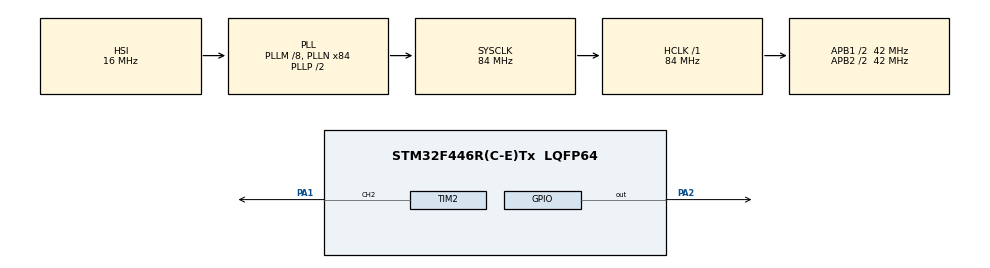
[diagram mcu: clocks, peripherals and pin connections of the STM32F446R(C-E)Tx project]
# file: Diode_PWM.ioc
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Mcu.Family=STM32F4
Mcu.Name=STM32F446R(C-E)Tx
Mcu.Package=LQFP64
NVIC.PriorityGroup=NVIC_PRIORITYGROUP_4
PA0-WKUP.Signal=S_TIM2_CH1_ETR
PA1.Signal=S_TIM2_CH2
PA13.Mode=Serial_Wire
PA13.Signal=SYS_JTMS-SWDIO
PA14.Mode=Serial_Wire
PA14.Signal=SYS_JTCK-SWCLK
PA2.Signal=GPIO_Output
ProjectManager.HeapSize=0x200
ProjectManager.StackSize=0x400
ProjectManager.TargetToolchain=STM32CubeIDE
RCC.AHBFreq_Value=84000000
RCC.APB1CLKDivider=RCC_HCLK_DIV2
RCC.APB1Freq_Value=42000000
RCC.APB1TimFreq_Value=84000000
RCC.APB2CLKDivider=RCC_HCLK_DIV2
RCC.APB2Freq_Value=42000000
RCC.APB2TimFreq_Value=84000000
RCC.CortexFreq_Value=84000000
RCC.HCLKFreq_Value=84000000
RCC.PLLM=8
RCC.PLLN=84
RCC.SYSCLKFreq_VALUE=84000000
RCC.SYSCLKSource=RCC_SYSCLKSOURCE_PLLCLK
RCC.USBFreq_Value=84000000
RCC.VCOOutputFreq_Value=168000000
SH.S_TIM2_CH1_ETR.0=TIM2_CH1
SH.S_TIM2_CH2.0=TIM2_CH2,PWM Generation2 CH2
TIM2.Channel-PWM\ Generation2\ CH2=TIM_CHANNEL_2
TIM2.Period=127
TIM2.Prescaler=84
board=custom

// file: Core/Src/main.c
/* USER CODE BEGIN Header */
/**
  ******************************************************************************
  * @file           : main.c
  * @brief          : Main program body
  *

  ******************************************************************************
  * @attention
  *
  * <h2><center>&copy; Copyright (c) 2021 STMicroelectronics.
  * All rights reserved.</center></h2>
  *
  * This software component is licensed by ST under BSD 3-Clause license,
  * the "License"; You may not use this file except in compliance with the
  * License. You may obtain a copy of the License at:
  *                        opensource.org/licenses/BSD-3-Clause
  *
  ******************************************************************************
  */
/* USER CODE END Header */
#include "main.h"
#include "stdio.h"

TIM_HandleTypeDef htim2;

/* USER CODE BEGIN PV */
	uint16_t pwm_value = 0;
	int8_t step = 0;
/* USER CODE END PV */

void SystemClock_Config(void);
static void MX_GPIO_Init(void);
static void MX_TIM2_Init(void);
/* USER CODE BEGIN PFP */
	void setPWM(uint16_t pwm_value);
/* USER CODE END PFP */

int main(void)
{

  /* MCU Configuration--------------------------------------------------------*/

  /* Reset of all peripherals, Initializes the Flash interface and the Systick. */
  HAL_Init();

  /* Configure the system clock */
  SystemClock_Config();

  /* Initialize all configured peripherals */
  MX_GPIO_Init();
  MX_TIM2_Init();
  /* USER CODE BEGIN 2 */
  HAL_TIM_PWM_Start(&htim2, TIM_CHANNEL_2);
  /* USER CODE END 2 */

  /* Infinite loop */
  while (1)
  {

    /* USER CODE BEGIN 3 */
	  if(pwm_value == 0) step = 1;
	  if(pwm_value == 127) step = -1;
	  pwm_value += step;
	  setPWM(pwm_value);
  	  HAL_Delay(5);
  }
  /* USER CODE END 3 */
}

void SystemClock_Config(void)
{
  RCC_OscInitTypeDef RCC_OscInitStruct = {0};
  RCC_ClkInitTypeDef RCC_ClkInitStruct = {0};

  /** Configure the main internal regulator output voltage
  */
  __HAL_RCC_PWR_CLK_ENABLE();
  __HAL_PWR_VOLTAGESCALING_CONFIG(PWR_REGULATOR_VOLTAGE_SCALE3);
  /** Initializes the RCC Oscillators according to the specified parameters
  * in the RCC_OscInitTypeDef structure.
  */
  RCC_OscInitStruct.OscillatorType = RCC_OSCILLATORTYPE_HSI;
  RCC_OscInitStruct.HSIState = RCC_HSI_ON;
  RCC_OscInitStruct.HSICalibrationValue = RCC_HSICALIBRATION_DEFAULT;
  RCC_OscInitStruct.PLL.PLLState = RCC_PLL_ON;
  RCC_OscInitStruct.PLL.PLLSource = RCC_PLLSOURCE_HSI;
  RCC_OscInitStruct.PLL.PLLM = 8;
  RCC_OscInitStruct.PLL.PLLN = 84;
  RCC_OscInitStruct.PLL.PLLP = RCC_PLLP_DIV2;
  RCC_OscInitStruct.PLL.PLLQ = 2;
  RCC_OscInitStruct.PLL.PLLR = 2;
  if (HAL_RCC_OscConfig(&RCC_OscInitStruct) != HAL_OK)
  {
    Error_Handler();
  }
  /** Initializes the CPU, AHB and APB buses clocks
  */
  RCC_ClkInitStruct.ClockType = RCC_CLOCKTYPE_HCLK|RCC_CLOCKTYPE_SYSCLK
                              |RCC_CLOCKTYPE_PCLK1|RCC_CLOCKTYPE_PCLK2;
  RCC_ClkInitStruct.SYSCLKSource = RCC_SYSCLKSOURCE_PLLCLK;
  RCC_ClkInitStruct.AHBCLKDivider = RCC_SYSCLK_DIV1;
  RCC_ClkInitStruct.APB1CLKDivider = RCC_HCLK_DIV2;
  RCC_ClkInitStruct.APB2CLKDivider = RCC_HCLK_DIV2;

  if (HAL_RCC_ClockConfig(&RCC_ClkInitStruct, FLASH_LATENCY_2) != HAL_OK)
  {
    Error_Handler();
  }
}

static void MX_TIM2_Init(void)
{

  TIM_MasterConfigTypeDef sMasterConfig = {0};
  TIM_OC_InitTypeDef sConfigOC = {0};

  htim2.Instance = TIM2;
  htim2.Init.Prescaler = 84;
  htim2.Init.CounterMode = TIM_COUNTERMODE_UP;
  htim2.Init.Period = 127;
  htim2.Init.ClockDivision = TIM_CLOCKDIVISION_DIV1;
  htim2.Init.AutoReloadPreload = TIM_AUTORELOAD_PRELOAD_DISABLE;
  if (HAL_TIM_PWM_Init(&htim2) != HAL_OK)
  {
    Error_Handler();
  }
  sMasterConfig.MasterOutputTrigger = TIM_TRGO_RESET;
  sMasterConfig.MasterSlaveMode = TIM_MASTERSLAVEMODE_DISABLE;
  if (HAL_TIMEx_MasterConfigSynchronization(&htim2, &sMasterConfig) != HAL_OK)
  {
    Error_Handler();
  }
  sConfigOC.OCMode = TIM_OCMODE_PWM1;
  sConfigOC.Pulse = 0;
  sConfigOC.OCPolarity = TIM_OCPOLARITY_HIGH;
  sConfigOC.OCFastMode = TIM_OCFAST_DISABLE;
  if (HAL_TIM_PWM_ConfigChannel(&htim2, &sConfigOC, TIM_CHANNEL_2) != HAL_OK)
  {
    Error_Handler();
  }
  HAL_TIM_MspPostInit(&htim2);

}

static void MX_GPIO_Init(void)
{
  GPIO_InitTypeDef GPIO_InitStruct = {0};

  /* GPIO Ports Clock Enable */
  __HAL_RCC_GPIOA_CLK_ENABLE();

  /*Configure GPIO pin Output Level */
  HAL_GPIO_WritePin(GPIOA, GPIO_PIN_2, GPIO_PIN_RESET);

  /*Configure GPIO pin : PA2 */
  GPIO_InitStruct.Pin = GPIO_PIN_2;
  GPIO_InitStruct.Mode = GPIO_MODE_OUTPUT_PP;
  GPIO_InitStruct.Pull = GPIO_NOPULL;
  GPIO_InitStruct.Speed = GPIO_SPEED_FREQ_LOW;
  HAL_GPIO_Init(GPIOA, &GPIO_InitStruct);

}

/* USER CODE BEGIN 4 */
void setPWM(uint16_t value)
{
    TIM_OC_InitTypeDef sConfigOC;

    sConfigOC.OCMode = TIM_OCMODE_PWM1;
    sConfigOC.Pulse = value;
    sConfigOC.OCPolarity = TIM_OCPOLARITY_HIGH;
    sConfigOC.OCFastMode = TIM_OCFAST_DISABLE;
    HAL_TIM_PWM_ConfigChannel(&htim2, &sConfigOC, TIM_CHANNEL_2); // таймер №2, канал №2
    HAL_TIM_PWM_Start(&htim2, TIM_CHANNEL_2);
}
/* USER CODE END 4 */

void Error_Handler(void)
{
  __disable_irq();
  while (1)
  {
  }
}

/************************ (C) COPYRIGHT STMicroelectronics *****END OF FILE****/
